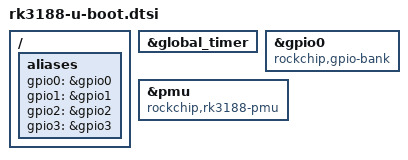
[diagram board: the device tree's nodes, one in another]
// SPDX-License-Identifier: GPL-2.0+
/*
 * Copyright (C) 2019 Jagan Teki <jagan@amarulasolutions.com>
 */

#include "rockchip-u-boot.dtsi"
#include "rk3xxx-u-boot.dtsi"

/ {
	aliases {
		gpio0 = &gpio0;
		gpio1 = &gpio1;
		gpio2 = &gpio2;
		gpio3 = &gpio3;
	};
};

&global_timer {
	status = "okay";
};

&gpio0 {
	compatible = "rockchip,gpio-bank";
};

&pmu {
	compatible = "rockchip,rk3188-pmu", "syscon", "simple-mfd";
};

